# CY8C5287AXI_LP095 register map
File version: 0.1
Registers are 8-bit, read-write, no defined reset value unless marked. A register's access mark holds for its fields unless they carry their own. Offsets are from the block's base; [hi:lo] are bit positions; 'fields as' and 'values as' point back to an identical list.

## ExtSRAMCtl
Base 0x00000000
0x40006475 ExtSRAMCtl_CONTROL_REG

## BankMask
Base 0x00000000
0x4000647E BankMask_CONTROL_REG

## AdrHighOut
Base 0x00000000
0x4000647A AdrHighOut_CONTROL_REG

## AdrLowOut
Base 0x00000000
0x40006471 AdrLowOut_CONTROL_REG

## IO_Ctrl_Reg
Base 0x00000000
0x40006474 IO_Ctrl_Reg_CONTROL_REG

## UART_1 — UART
Base 0x00000000
0x40006441 TX_UART_1_TX_DATA — TX Data Register
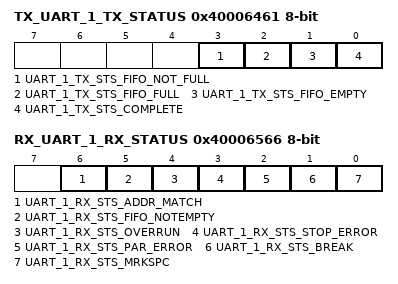
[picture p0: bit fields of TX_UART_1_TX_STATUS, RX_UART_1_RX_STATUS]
0x40006461 TX_UART_1_TX_STATUS — TX status register
  [3] UART_1_TX_STS_FIFO_NOT_FULL ro, [2] UART_1_TX_STS_FIFO_FULL ro, [1] UART_1_TX_STS_FIFO_EMPTY ro, [0] UART_1_TX_STS_COMPLETE ro
0x40006525 RX_UART_1_RX_ADDRESS1 — RX Address1 Register
0x40006535 RX_UART_1_RX_ADDRESS2 — RX Address2 Register
0x40006545 RX_UART_1_RX_DATA — RX Data Register
0x40006566 RX_UART_1_RX_STATUS — RX status register
  [6] UART_1_RX_STS_ADDR_MATCH ro, [5] UART_1_RX_STS_FIFO_NOTEMPTY ro, [4] UART_1_RX_STS_OVERRUN ro, [3] UART_1_RX_STS_STOP_ERROR ro, [2] UART_1_RX_STS_PAR_ERROR ro, [1] UART_1_RX_STS_BREAK ro, [0] UART_1_RX_STS_MRKSPC ro

## AdrLowIn
Base 0x00000000
0x4000646C AdrLowIn_STATUS_REG
0x4000648C AdrLowIn_MASK_REG
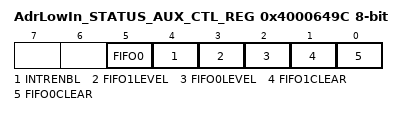
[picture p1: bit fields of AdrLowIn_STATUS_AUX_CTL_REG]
0x4000649C AdrLowIn_STATUS_AUX_CTL_REG
  [5] FIFO0 — FIFO0 clear
    1=ENABLED (Enable counter); 0=DISABLED (Disable counter)
  [4] INTRENBL — Enables or disables the Interrupt
    1=ENABLED (Interrupt enabled); 0=DISABLED (Interrupt disabled)
  [3] FIFO1LEVEL — FIFO level
    1=ENABLED (FIFO LVL: input mode: FIFO at least 1/2 empty; output mode: FIFO at least 1/2 full); 0=DISABLED (FIFO LVL: input mode: FIFO not full; output mode: FIFO not empty)
  [2] FIFO0LEVEL — FIFO level
    values as FIFO1LEVEL
  [1] FIFO1CLEAR — FIFO clear
    1=ENABLED (Clear FIFO state); 0=DISABLED (Normal FIFO operation)
  [0] FIFO0CLEAR — FIFO clear
    values as FIFO1CLEAR

## Z80_Data_Out
Base 0x00000000
0x40006564 Z80_Data_Out_STATUS_REG
0x40006584 Z80_Data_Out_MASK_REG
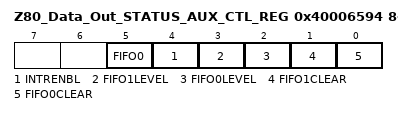
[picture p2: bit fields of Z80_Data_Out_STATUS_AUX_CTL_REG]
0x40006594 Z80_Data_Out_STATUS_AUX_CTL_REG
  [5] FIFO0 — FIFO0 clear
    1=ENABLED (Enable counter); 0=DISABLED (Disable counter)
  [4] INTRENBL — Enables or disables the Interrupt
    1=ENABLED (Interrupt enabled); 0=DISABLED (Interrupt disabled)
  [3] FIFO1LEVEL — FIFO level
    1=ENABLED (FIFO LVL: input mode: FIFO at least 1/2 empty; output mode: FIFO at least 1/2 full); 0=DISABLED (FIFO LVL: input mode: FIFO not full; output mode: FIFO not empty)
  [2] FIFO0LEVEL — FIFO level
    values as FIFO1LEVEL
  [1] FIFO1CLEAR — FIFO clear
    1=ENABLED (Clear FIFO state); 0=DISABLED (Normal FIFO operation)
  [0] FIFO0CLEAR — FIFO clear
    values as FIFO1CLEAR

## Z80_Data_In
Base 0x00000000
0x40006479 Z80_Data_In_CONTROL_REG

## AdrMidOut
Base 0x00000000
0x4000647D AdrMidOut_CONTROL_REG

## I2C
Base 0x00000000
0x40006408 I2C_DATA
  [7:0] data — Read received data or write data to transmit.
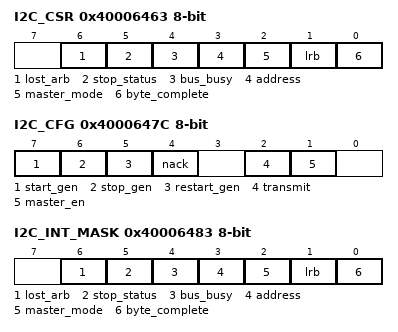
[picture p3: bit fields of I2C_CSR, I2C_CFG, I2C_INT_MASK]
0x40006463 I2C_CSR — I2C Status Register
  [6] lost_arb ro — If set, indicates arbitration was lost (multi-master and multi-master-slave modes).
  [5] stop_status ro — If set, indicates a Stop condition was detected on the bus.
  [4] bus_busy ro — If set, indicates the bus is busy. Data is currently being transmitted or received.
  [3] address ro — Address detection. If set, indicates that an address byte was sent.
  [2] master_mode ro — Indicates that a valid Start condition was generated and a hardware device is operating as bus master.
  [1] lrb ro — Last Received Bit. Indicates the state of the last received bit, which is the ACK/NAK received for the last byte transmitted. Cleared = ACK and set = NAK.
  [0] byte_complete ro — Transmit or receive status since the last read of this register. In Transmit mode this bit indicates that eight bits of data plus ACK/NAK have been transmitted since the last read. In Receive mode this bit indicates that eight bits of data have been received since the last read of this register.
0x4000647C I2C_CFG — I2C Configuration Register
  [7] start_gen — Set to 1 to generate a Start condition on the bus. This bit must be cleared by firmware before initiating the next transaction.
  [6] stop_gen — Set to 1 to generate a Stop condition on the bus. This bit must be cleared by firmware before initiating the next transaction.
  [5] restart_gen — Set to 1 to generate a Restart condition on the bus. This bit must be cleared by firmware after a Restart condition is generated.
  [4] nack — Set to 1 to NAK the next read byte. Clear to ACK next read byte. This bit must be cleared by firmware between bytes.
  [2] transmit — Set to 1 to set the current mode to transmit or clear to 0 to receive a byte of data. This bit must be cleared by firmware before starting the next transmit or receive transaction.
  [1] master_en — Set to 1 to enable the master functionality.
0x40006483 I2C_INT_MASK — I2C Interrupt Enable Mask
  [6] lost_arb — Enables interrupt from the corresponding bit in status register.
  [5] stop_status — Enables interrupt from the corresponding bit in status register.
  [4] bus_busy — Enables interrupt from the corresponding bit in status register.
  [3] address — Enables interrupt from the corresponding bit in status register.
  [2] master_mode — Enables interrupt from the corresponding bit in status register.
  [1] lrb — Enables interrupt from the corresponding bit in status register.
  [0] byte_complete — Enables interrupt from the corresponding bit in status register.

## BankBaseAdr
Base 0x00000000
0x4000647F BankBaseAdr_CONTROL_REG
